# N572F072_v3 register map
File version: 1.0
N572F072_v3 SVD file
Registers are 32-bit, read-write, reset 0x0 unless marked. A register's access mark holds for its fields unless they carry their own. Offsets are from the block's base; lines under a group give offsets from that group; [hi:lo] are bit positions; {n}, {i} and the like mark numbered series; 'fields as' and 'values as' point back to an identical list; <NAME> marks a mode.

## Memory map
0x00300000 CFG size 0x4 — CONFIGURE Register Map
0x40004000 WDT size 0x4 — WDT Register Map
0x40008000 RTC size 0x4 — RTC Register Map
0x40010000 TMR blocks up to offset 0x50 — TMR Register Map
0x40030000 SPI0 blocks up to offset 0x34 — SPI Register Map
0x40034000 SPI1 blocks up to offset 0x28 — SPI Register Map
0x40040000 PWM blocks up to offset 0x80 — PWM Register Map
0x400E0000 ADC blocks up to offset 0x44 — ADC Register Map
0x50000000 SYS blocks up to offset 0x104 — SYS Register Map
0x50000200 CLK blocks up to offset 0x24 — CLK Register Map
0x50000300 INT blocks up to offset 0x88 — INT Register Map
0x50004000 GPIO blocks up to offset 0x64 — GPIO Register Map
0x50008000 APU blocks up to offset 0x30 — APU Register Map
0x5000C000 FMC size 0x14 — FMC Register Map
0xE000E000 SCS blocks up to offset 0x410 — SCS Register Map

## INT — INT Register Map
Base 0x50000300
0x00 IRQ0_SRC ro reset not defined — IRQ0 (WDT) Interrupt Source Identity Register
  [2:0] INT_SRC — Interrupt Source Identity. Bit2: 0. Bit1: 0. Bit0: WDT_INT
0x04 IRQ1_SRC ro reset not defined — IRQ1 (APU) Interrupt Source Identity Register
  [2:0] INT_SRC — Interrupt Source Identity. Bit2: 0. Bit1: 0. Bit0: APU_INT
0x08 IRQ2_SRC ro reset not defined — IRQ2 (ADC) Interrupt Source Identity Register
  [2:0] INT_SRC — Interrupt Source Identity. Bit2: 0. Bit1: 0. Bit0: ADC_INT
0x0C IRQ3_SRC ro reset not defined — IRQ3 (EXINT) Interrupt Source Identity Register
  [2:0] INT_SRC — Interrupt Source Identity. Bit2: 0. Bit1: 0. Bit0: External interrupt
{0x0+4i} IRQ{i}_SRC ro reset not defined (i=5..7) — IRQ{i} (Timer{i-5}) Interrupt Source Identity Register
  [2:0] INT_SRC — Interrupt Source Identity. Bit2: 0. Bit1: 0. Bit0: Timer{i-5}_INT
0x20 IRQ8_SRC ro reset not defined — IRQ8 (GPA/B) Interrupt Source Identity Register
  [2:0] INT_SRC — Interrupt Source Identity. Bit2: 0. Bit1: GPB_INT. Bit0: GPA_INT
0x24 IRQ9_SRC ro reset not defined — IRQ9 (SPI0) Interrupt Source Identity Register
  [2:0] INT_SRC — Interrupt Source Identity. Bit2: 0. Bit1: 0. Bit0: SPI0_INT
0x28 IRQ10_SRC ro reset not defined — IRQ10 (PWM) Interrupt Source Identity Register
  [2:0] INT_SRC — Interrupt Source Identity. Bit2: 0. Bit1: 0. Bit0: PWM_INT
0x2C IRQ11_SRC ro reset not defined — IRQ11 (SPI1) Interrupt Source Identity Register
  [2:0] INT_SRC — Interrupt Source Identity. Bit2: 0. Bit1: 0. Bit0: SPI1_INT
0x30 IRQ12_SRC ro reset not defined — IRQ12 (TimerF) Interrupt Source Identity Register
  [2:0] INT_SRC — Interrupt Source Identity. Bit2: 0. Bit1: 0. Bit0: TimerF_INT
0x34 IRQ13_SRC ro reset not defined — IRQ13 (RTC) Interrupt Source Identity Register
  [2:0] INT_SRC — Interrupt Source Identity. Bit2: 0. Bit1: 0. Bit0: RTC_INT
0x38 IRQ14_SRC ro reset not defined — IRQ14 (PWRWU) Interrupt Source Identity Register
  [2:0] INT_SRC — Interrupt Source Identity. Bit2: 0. Bit1: 0. Bit0: PWRWU_INT
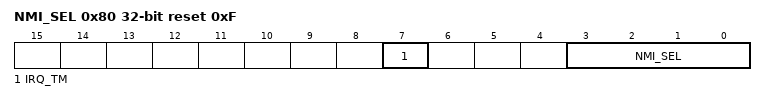
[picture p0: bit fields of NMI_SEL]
0x80 NMI_SEL reset 0xF — NMI Source Interrupt Select Control Register
  [7] IRQ_TM — IRQ Test Mode. This bit is the protected bit. To program this bit needs an open lock sequence, write "59h", "16h", "88h" to register SYS_REGLCTL to un-lock this bit. Refer to the register SYS_REGLCTL at address SYS_BA+0x100.
    0=The interrupt register MCU_IRQ operates in normal mode. The MCU_IRQ collects all the interrupts from the peripheral and generates interrupt to MCU; 1=All the interrupts from peripheral to MCU are blocked. The peripheral IRQ signals (0-15) are replaced by the value in the MCU_IRQ register
  [3:0] NMI_SEL — NMI Source Interrupt Select. The NMI interrupt to Cortex-M0 can be selected from one of the interrupt[15:0]. The NMI_SEL bit is used to select the NMI interrupt source. Note: IRQ4 and IRQ15 are reserved in N572F072/P072.
0x84 MCU_IRQ — MCU IRQ Number Identify Register
  [15:0] MCU_IRQ — MCU IRQ Source Test Mode. The MCU_IRQ collects all the interrupts from the peripherals and generates the synchronous interrupt to MCU Cortex-M0. There are two modes to generate interrupt to MCU Cortex-M0, the normal mode and test mode. When MCU_IRQ[n] is "0" : Writing MCU_IRQ[n] "1" will generate an interrupt to Cortex_M0 IRQ[n]. When MCU_IRQ[n] is "1" (meaning an interrupt is asserted): Writing MCU_IRQ[n] "1" will clear the interrupt. Writing MCU_IRQ[n] "0": has no effect. Note: IRQ4 and IRQ15 are reserved in N572F072/P072.
